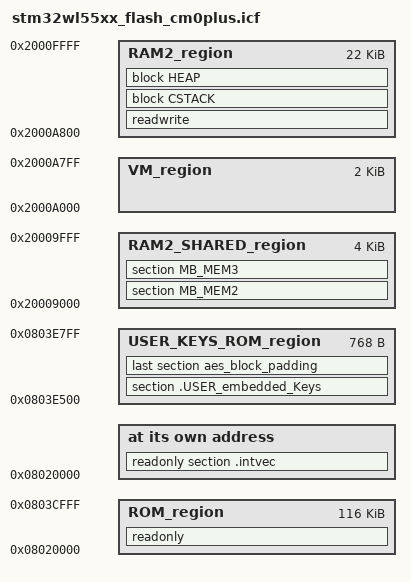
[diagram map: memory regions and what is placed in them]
/*###ICF### Section handled by ICF editor, don't touch! ****/
/*-Editor annotation file-*/
/* IcfEditorFile="$TOOLKIT_DIR$\config\ide\IcfEditor\cortex_v1_0.xml" */
/*-Specials-*/
define symbol __ICFEDIT_intvec_start__ = 0x08020000;

/*-Memory Regions-*/
/***** FLASH part dedicated to M0+ *****/
define symbol __ICFEDIT_region_ROM_start__    = 0x08020000;
define symbol __ICFEDIT_region_ROM_end__      = 0x0803CFFF;
define symbol __ICFEDIT_region_User_Keys_region_ROM_start__   = 0x0803E500;
define symbol __ICFEDIT_region_User_Keys_region_ROM_end__     = 0x0803E7FF;
/***** SRAM2 shared allocated by M0+ *****/
define symbol __ICFEDIT_region_RAM2_SHARED_start__ = 0x20009000;
define symbol __ICFEDIT_region_RAM2_SHARED_end__   = 0x20009FFF;
/***** SRAM2 dedicated to M0+ *****/
define symbol __ICFEDIT_region_RAM2_start__   = 0x2000A800;
define symbol __ICFEDIT_region_RAM2_end__     = 0x2000FFFF;

/* KMS Data Storage (VMS) region */
/* WARNING: Symbols not used */
/* The VMS address is defined in vms_low_level.h: VMS_KMS_DATA_STORAGE_START */
define exported symbol __ICFEDIT_VM_KMS_DataStorage_start__ = 0x2000A000;
define exported symbol __ICFEDIT_VM_KMS_DataStorage_end__   = 0x2000A7FF;

/*-Sizes-*/
define symbol __ICFEDIT_size_cstack__ = 0x1000;
define symbol __ICFEDIT_size_heap__   = 0x400;
/**** End of ICF editor section. ###ICF###*/


define memory mem with size = 4G;
define region ROM_region      = mem:[from __ICFEDIT_region_ROM_start__   to __ICFEDIT_region_ROM_end__];
define region USER_KEYS_ROM_region     = mem:[from __ICFEDIT_region_User_Keys_region_ROM_start__   to __ICFEDIT_region_User_Keys_region_ROM_end__];
define region RAM2_SHARED_region = mem:[from __ICFEDIT_region_RAM2_SHARED_start__  to __ICFEDIT_region_RAM2_SHARED_end__];
define region RAM2_region     = mem:[from __ICFEDIT_region_RAM2_start__  to __ICFEDIT_region_RAM2_end__];
define region VM_region       = mem:[from __ICFEDIT_VM_KMS_DataStorage_start__   to __ICFEDIT_VM_KMS_DataStorage_end__];

define block CSTACK    with alignment = 8, size = __ICFEDIT_size_cstack__   { };
define block HEAP      with alignment = 8, size = __ICFEDIT_size_heap__     { };

initialize by copy { readwrite };
do not initialize  { section .noinit,
                     section MB_MEM2,
                     section MB_MEM3 };
/* to make sure the binary size is a multiple of the AES block size (16 bytes) */
define root section aes_block_padding with alignment=16
{
udata8 "Force Alignment";
pad_to 16;
};

place at address mem:__ICFEDIT_intvec_start__ { readonly section .intvec };

place in ROM_region   { readonly };
place in USER_KEYS_ROM_region { section .USER_embedded_Keys, last section aes_block_padding };
keep { section .SE_embedded_Keys };
place in RAM2_region  { readwrite,
                        block CSTACK, block HEAP };
place in RAM2_SHARED_region  { section MB_MEM2, section MB_MEM3 };
place in VM_region    { };
